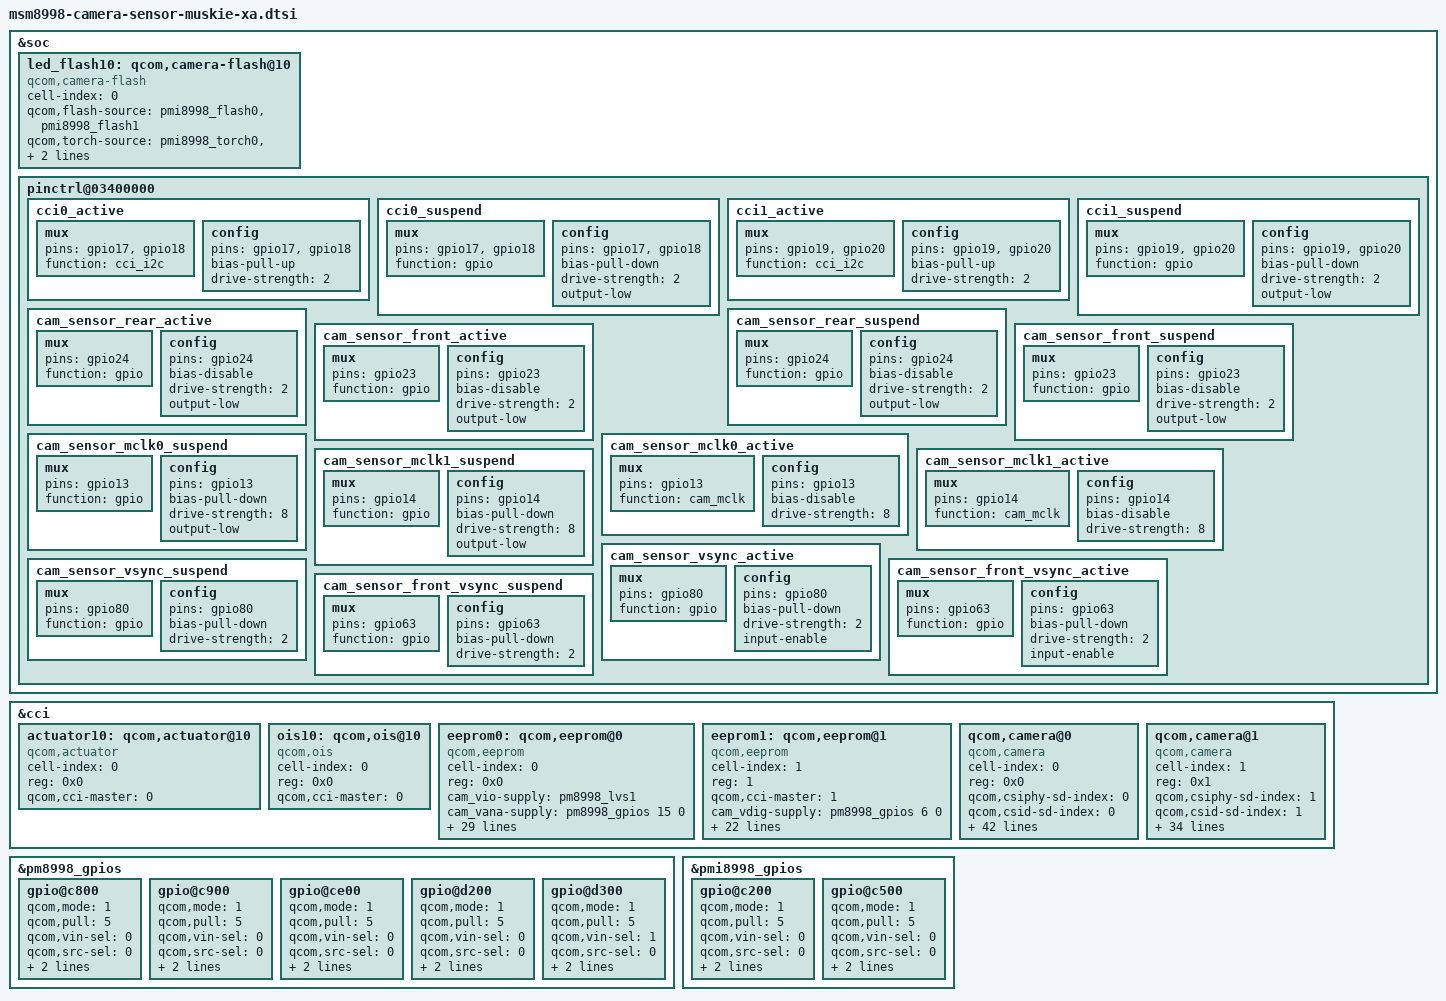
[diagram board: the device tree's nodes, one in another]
/*
 * Copyright (c) 2016, The Linux Foundation. All rights reserved.
 *
 * This program is free software; you can redistribute it and/or modify
 * it under the terms of the GNU General Public License version 2 and
 * only version 2 as published by the Free Software Foundation.
 *
 * This program is distributed in the hope that it will be useful,
 * but WITHOUT ANY WARRANTY; without even the implied warranty of
 * MERCHANTABILITY or FITNESS FOR A PARTICULAR PURPOSE.  See the
 * GNU General Public License for more details.
 */

&soc {
	led_flash10: qcom,camera-flash@10 {
		cell-index = <0>;
		compatible = "qcom,camera-flash";
		qcom,flash-source = <&pmi8998_flash0 &pmi8998_flash1>;
		qcom,torch-source = <&pmi8998_torch0 &pmi8998_torch1>;
		qcom,switch-source = <&pmi8998_switch0>;
		status = "ok";
	};

	pinctrl@03400000 {
		cci0_active {
			mux {
				/* CLK, DATA */
				pins = "gpio17","gpio18"; // Only 2
				function = "cci_i2c";
			};

			config {
				pins = "gpio17","gpio18";
				bias-pull-up; /* PULL UP*/
				drive-strength = <2>; /* 2 MA */
			};
		};

		cci0_suspend {
			mux {
				/* CLK, DATA */
				pins = "gpio17","gpio18";
				function = "gpio";
			};

			config {
				pins = "gpio17","gpio18";
				bias-pull-down; /* PULL DOWN */
				drive-strength = <2>; /* 2 MA */
				output-low; /*HTC ADD*/
			};
		};

		cci1_active {
			mux {
				/* CLK, DATA */
				pins = "gpio19","gpio20";
				function = "cci_i2c";
			};

			config {
				pins = "gpio19","gpio20";
				bias-pull-up; /* PULL UP*/
				drive-strength = <2>; /* 2 MA */
			};
		};

		cci1_suspend {
			mux {
				/* CLK, DATA */
				pins = "gpio19","gpio20";
				function = "gpio";
			};

			config {
				pins = "gpio19","gpio20";
				bias-pull-down; /* PULL DOWN */
				drive-strength = <2>; /* 2 MA */
				output-low; /*HTC ADD*/
			};
		};

		cam_sensor_rear_active {
			/* RESET, STANDBY */
			mux {
				pins = "gpio24";	/*HTC modify */
				function = "gpio";
			};

			config {
				pins = "gpio24";	/*HTC modify */
				bias-disable; /* No PULL */
				drive-strength = <2>; /* 2 MA */
				output-low;			/*HTC ADD*/
			};
		};

		cam_sensor_rear_suspend{
			/* RESET, STANDBY */
			mux {
				pins = "gpio24";	/*HTC modify */
				function = "gpio";
			};

			config {
				pins = "gpio24";	/*HTC modify */
				bias-disable; /* No PULL */
				drive-strength = <2>; /* 2 MA */
				output-low;			/*HTC ADD*/
			};
		};

		cam_sensor_front_active {
			/* RESET, STANDBY */
			mux {
				pins = "gpio23";	/*HTC modify */
				function = "gpio";
			};

			config {
				pins = "gpio23";	/*HTC modify */
				bias-disable; /* No PULL */
				drive-strength = <2>; /* 2 MA */
				output-low;			/*HTC ADD*/
			};
		};

		cam_sensor_front_suspend {
			/* RESET, STANDBY */
			mux {
				pins = "gpio23";	/*HTC modify */
				function = "gpio";
			};
			config {
				pins = "gpio23";	/*HTC modify */
				bias-disable; /* No PULL */
				drive-strength = <2>; /* 2 MA */
				output-low;			/*HTC ADD*/
			};
		};

		cam_sensor_mclk0_active {
			/* MCLK0 */
			mux {
				/* CLK, DATA */
				pins = "gpio13";
				function = "cam_mclk";
			};

			config {
				pins = "gpio13";
				bias-disable; /* No PULL */
				drive-strength = <8>; /* 2 MA */
			};
		};

		cam_sensor_mclk0_suspend {
			/* MCLK0 */
			mux {
				/* CLK, DATA */
				pins = "gpio13";
				function = "gpio";
			};

			config {
				pins = "gpio13";
				bias-pull-down; /* PULL DOWN */
				drive-strength = <8>; /* 2 MA */
				output-low; /*HTC ADD*/
			};
		};

		cam_sensor_mclk1_active {
			/* MCLK1 */
			mux {
				/* CLK, DATA */
				pins = "gpio14";
				function = "cam_mclk";
			};

			config {
				pins = "gpio14";
				bias-disable; /* No PULL */
				drive-strength = <8>; /* HTC modify 8 MA */
			};
		};

		cam_sensor_mclk1_suspend {
			/* MCLK1 */
			mux {
				/* CLK, DATA */
				pins = "gpio14";
				function = "gpio";
			};

			config {
				pins = "gpio14";
				bias-pull-down; /* PULL DOWN */
				drive-strength = <8>; /* HTC modify 8 MA */
				output-low; /*HTC ADD*/
			};
		};

		cam_sensor_vsync_active: cam_sensor_vsync_active {
			/* Main VSYNC */
			mux {
				pins = "gpio80";
				function = "gpio";
			};

			config {
				pins = "gpio80";
				bias-pull-down; /* PULL DOWN */
				drive-strength = <2>; /* 2 MA */
				input-enable;
			};
		};

		cam_sensor_vsync_suspend: cam_sensor_vsync_suspend {
			/* Main VSYNC */
			mux {
				pins = "gpio80";
				function = "gpio";
			};

			config {
				pins = "gpio80";
				bias-pull-down; /* PULL DOWN */
				drive-strength = <2>; /* 2 MA */
			};
		};

		cam_sensor_front_vsync_active: cam_sensor_front_vsync_active {
			/* Front VSYNC */
			mux {
				pins = "gpio63";
				function = "gpio";
			};

			config {
				pins = "gpio63";
				bias-pull-down; /* PULL DOWN */
				drive-strength = <2>; /* 2 MA */
				input-enable;
			};
		};

		cam_sensor_front_vsync_suspend: cam_sensor_front_vsync_suspend {
			/* Front VSYNC */
			mux {
				pins = "gpio63";
				function = "gpio";
			};

			config {
				pins = "gpio63";
				bias-pull-down; /* PULL DOWN */
				drive-strength = <2>; /* 2 MA */
			};
		};
	};
};

&cci {
	actuator10: qcom,actuator@10 {
		cell-index = <0>;
		reg = <0x0>;
		compatible = "qcom,actuator";
		qcom,cci-master = <0>;
	};

	ois10: qcom,ois@10 {
		cell-index = <0>;
		reg = <0x0>;
		compatible = "qcom,ois";
		qcom,cci-master = <0>;
		status = "ok";
	};

	eeprom0: qcom,eeprom@0 {
		cell-index = <0>;
		compatible = "qcom,eeprom";
		reg = <0x0>;
		cam_vio-supply = <&pm8998_lvs1>;
		cam_vana-supply = <&pm8998_gpios 15 0>;
		cam_vdig-supply = <&pm8998_gpios 20 0>;
		qcom,cam-vreg-name = "cam_vio", "cam_vana", "cam_vdig";
		qcom,cam-vreg-min-voltage = <1800000 2850000 1050000>;
		qcom,cam-vreg-max-voltage = <1800000 2850000 1050000>;
		qcom,cam-vreg-op-mode = <0 0 0>;
		qcom,gpio-no-mux = <0>;
		gpios = <&tlmm 13 0>,
			<&tlmm 24 0>,
			<&pm8998_gpios 20 0>,
			<&pm8998_gpios 15 0>,
			<&pm8998_gpios 10 0>,
			<&pm8998_gpios 19 0>,
			<&pm8998_gpios 9 0>;
		qcom,gpio-reset = <1>;
		qcom,gpio-vdig = <2>;
		qcom,gpio-vana = <3>;
		qcom,gpio-vaf = <4>;
		qcom,gpio-custom1 = <5>;
		qcom,gpio-custom2 = <6>;
		qcom,gpio-req-tbl-num = <0 1 2 3 4 5 6>;
		qcom,gpio-req-tbl-flags = <1 0 0 0 0 0 0>;
		qcom,gpio-req-tbl-label = "CAMIF_MCLK0",
					"CAM_RESET0",
					"CAM1_VDIG",
					"CAM1_VANA",
					"CAM1_VAF",
					"CAM1_A1V8",
					"CAM1_DRV";
		qcom,sensor-position = <0>;
		qcom,sensor-mode = <0>;
		qcom,cci-master = <0>;
		status = "ok";
		clocks = <&clock_mmss clk_mclk0_clk_src>,
				<&clock_mmss clk_mmss_camss_mclk0_clk>;
		clock-names = "cam_src_clk", "cam_clk";
		qcom,clock-rates = <24000000 0>;
	};
	eeprom1: qcom,eeprom@1 {
		cell-index = <1>;
		reg = <1>;
		compatible = "qcom,eeprom";
		qcom,cci-master = <1>;
		cam_vdig-supply = <&pm8998_gpios 6 0>;//212mA
		cam_ana-suplly = <&pm8998_gpios 3 0>;
		cam_vio-supply = <&pm8998_lvs1>;//7mA
		qcom,cam-vreg-name = "cam_vdig", "cam_vio", "cam_vana";
		qcom,cam-vreg-min-voltage = <1200000 1800000 2850000>;
		qcom,cam-vreg-max-voltage = <1200000 1800000 2850000>;
		qcom,cam-vreg-op-mode = <0 0 0>;//uA
		qcom,gpio-no-mux = <0>;
		gpios = <&tlmm 14 0>,
			<&tlmm 23 0>,
			<&pmi8998_gpios 6 0>,
			<&pmi8998_gpios 3 0>;
		qcom,gpio-reset = <1>;
		qcom,gpio-vdig = <2>;
		qcom,gpio-vana = <3>;
		qcom,gpio-req-tbl-num = <0 1 2 3>;
		qcom,gpio-req-tbl-flags = <1 0 0 0>;
		qcom,gpio-req-tbl-label = "CAMIF_MCLK1",
					"CAM_RESET1",
					"CAM2_VDIG",
					"CAM2_VANA";
		clocks = <&clock_mmss clk_mclk1_clk_src>,
				<&clock_mmss clk_mmss_camss_mclk1_clk>;
		clock-names = "cam_src_clk", "cam_clk";
		qcom,clock-rates = <24000000 0>;
	};
	qcom,camera@0 {
		cell-index = <0>;
		compatible = "qcom,camera";
		reg = <0x0>;
		qcom,csiphy-sd-index = <0>;
		qcom,csid-sd-index = <0>;
		qcom,mount-angle = <90>;
		qcom,led-flash-src = <&led_flash10>;
		qcom,actuator-src = <&actuator10>;
		qcom,ois-src = <&ois10>;
		qcom,eeprom-src = <&eeprom0>;
		cam_vio-supply = <&pm8998_lvs1>;
		cam_vana-supply = <&pm8998_gpios 15 0>;
		cam_vdig-supply = <&pm8998_gpios 20 0>;
		qcom,cam-vreg-name = "cam_vio", "cam_vana", "cam_vdig";
		qcom,cam-vreg-min-voltage = <1800000 2850000 1050000>;
		qcom,cam-vreg-max-voltage = <1800000 2850000 1050000>;
		qcom,cam-vreg-op-mode = <0 0 0>;
		qcom,gpio-no-mux = <0>;
		pinctrl-names = "cam_default", "cam_suspend";
		pinctrl-0 = <&cam_sensor_mclk0_active
				 &cam_sensor_rear_active
				 &cam_sensor_vsync_active>;
		pinctrl-1 = <&cam_sensor_mclk0_suspend
				 &cam_sensor_rear_suspend
				 &cam_sensor_vsync_suspend>;
		gpios = <&tlmm 13 0>,
			<&tlmm 24 0>,
			<&pm8998_gpios 20 0>,
			<&pm8998_gpios 15 0>,
			<&pm8998_gpios 10 0>,
			<&pm8998_gpios 19 0>,
			<&pm8998_gpios 9 0>;
		qcom,gpio-reset = <1>;
		qcom,gpio-vdig = <2>;
		qcom,gpio-vana = <3>;
		qcom,gpio-vaf = <4>;
		qcom,gpio-custom1 = <5>;
		qcom,gpio-custom2 = <6>;
		qcom,gpio-req-tbl-num = <0 1 2 3 4 5 6>;
		qcom,gpio-req-tbl-flags = <1 0 0 0 0 0 0>;
		qcom,gpio-req-tbl-label = "CAMIF_MCLK0",
					"CAM_RESET0",
					"CAM1_VDIG",
					"CAM1_VANA",
					"CAM1_VAF",
					"CAM1_A1V8",
					"CAM1_DRV";
		qcom,sensor-position = <0>;
		qcom,sensor-mode = <0>;
		qcom,cci-master = <0>;
		status = "ok";
		clocks = <&clock_mmss clk_mclk0_clk_src>,
				<&clock_mmss clk_mmss_camss_mclk0_clk>;
		clock-names = "cam_src_clk", "cam_clk";
		qcom,clock-rates = <24000000 0>;
	};

	qcom,camera@1 {
		cell-index = <1>;
		compatible = "qcom,camera";
		reg = <0x1>;
		qcom,csiphy-sd-index = <1>;
		qcom,csid-sd-index = <1>;
		qcom,mount-angle = <270>;
		//qcom,led-flash-src = <&led_flash1>;
		//qcom,actuator-src = <&actuator1>;
		qcom,eeprom-src = <&eeprom1>;
		cam_vdig-supply = <&pmi8998_gpios 6 0>;//212mA
		cam_vio-supply = <&pm8998_lvs1>;//7mA
		cam_vana-supply = <&pmi8998_gpios 3 0>;
		qcom,cam-vreg-name = "cam_vdig", "cam_vio", "cam_vana";
		qcom,cam-vreg-min-voltage = <1200000 1800000 2850000>;
		qcom,cam-vreg-max-voltage = <1200000 1800000 2850000>;
		qcom,cam-vreg-op-mode = <0 0 0>;//uA
		qcom,gpio-no-mux = <0>;
		pinctrl-names = "cam_default", "cam_suspend";
		pinctrl-0 = <&cam_sensor_mclk1_active
			&cam_sensor_front_active
			&cam_sensor_front_vsync_active>;
		pinctrl-1 = <&cam_sensor_mclk1_suspend
			&cam_sensor_front_suspend
			&cam_sensor_front_vsync_suspend>;
		gpios = <&tlmm 14 0>,
			<&tlmm 23 0>,
			<&pmi8998_gpios 6 0>,
			<&pmi8998_gpios 3 0>;
		qcom,gpio-reset = <1>;
		qcom,gpio-vdig = <2>;
		qcom,gpio-vana = <3>;
		qcom,gpio-req-tbl-num = <0 1 2 3>;
		qcom,gpio-req-tbl-flags = <1 0 0 0>;
		qcom,gpio-req-tbl-label = "CAMIF_MCLK1",
					"CAM_RESET1",
					"CAM2_VDIG",
					"CAM2_VANA";
		qcom,sensor-position = <1>;
		qcom,sensor-mode = <1>;
		qcom,cci-master = <1>;
		status = "ok";
		clocks = <&clock_mmss clk_mclk1_clk_src>,
				<&clock_mmss clk_mmss_camss_mclk1_clk>;
		clock-names = "cam_src_clk", "cam_clk";
		qcom,clock-rates = <24000000 0>;
	};
};
&pm8998_gpios {
	gpio@c800 { /* GPIO 9 - CAMERA SENSOR 0 DRV */
		qcom,mode = <1>;		/* Output */
		qcom,pull = <5>;		/* No Pull */
		qcom,vin-sel = <0>;		/* VIN1 GPIO_LV */
		qcom,src-sel = <0>;		/* GPIO */
		qcom,invert = <0>;		/* Invert */
		qcom,master-en = <1>;		/* Enable GPIO */
		status = "ok";
	};

	gpio@c900 { /* GPIO 10 - CAMERA SENSOR 0 VAF */
		qcom,mode = <1>;		/* Output */
		qcom,pull = <5>;		/* No Pull */
		qcom,vin-sel = <0>;		/* VIN1 GPIO_LV */
		qcom,src-sel = <0>;		/* GPIO */
		qcom,invert = <0>;		/* Invert */
		qcom,master-en = <1>;		/* Enable GPIO */
		status = "ok";
	};

	gpio@ce00 { /* GPIO 15 - CAMERA SENSOR 0 VANA */
		qcom,mode = <1>;		/* Output */
		qcom,pull = <5>;		/* No Pull */
		qcom,vin-sel = <0>;		/* VIN1 GPIO_LV */
		qcom,src-sel = <0>;		/* GPIO */
		qcom,invert = <1>;		/* Invert */
		qcom,master-en = <1>;		/* Enable GPIO */
		status = "ok";
	};

	gpio@d200 { /* GPIO 19 - CAMERA SENSOR 0 VANA_A1V8 */
		qcom,mode = <1>;		/* Output */
		qcom,pull = <5>;		/* No Pull */
		qcom,vin-sel = <0>;		/* VIN1 GPIO_LV */
		qcom,src-sel = <0>;		/* GPIO */
		qcom,invert = <1>;		/* Invert */
		qcom,master-en = <1>;		/* Enable GPIO */
		status = "ok";
	};

	gpio@d300 { /* GPIO 20 - CAMERA SENSOR 0 VDIG */
		qcom,mode = <1>;		/* Output */
		qcom,pull = <5>;		/* No Pull */
		qcom,vin-sel = <1>;		/* VIN1 GPIO_MV */
		qcom,src-sel = <0>;		/* GPIO */
		qcom,invert = <0>;		/* Invert */
		qcom,master-en = <1>;		/* Enable GPIO */
		status = "ok";
	};
};

&pmi8998_gpios {
	gpio@c200 { /* GPIO 3 - CAMERA SENSOR 1 VANA */
		qcom,mode = <1>;		/* Output */
		qcom,pull = <5>;		/* No Pull */
		qcom,vin-sel = <0>;		/* VIN1 GPIO_LV */
		qcom,src-sel = <0>;		/* GPIO */
		qcom,invert = <1>;		/* Invert */
		qcom,master-en = <1>;		/* Enable GPIO */
		status = "ok";
	};

	gpio@c500 { /* GPIO 6 - CAMERA SENSOR 1 VDIG */
		qcom,mode = <1>;		/* Output */
		qcom,pull = <5>;		/* No Pull */
		qcom,vin-sel = <0>;		/* VIN1 GPIO_LV */
		qcom,src-sel = <0>;		/* GPIO */
		qcom,invert = <1>;		/* Invert */
		qcom,master-en = <1>;		/* Enable GPIO */
		status = "ok";
	};
};
